# j7aen_main_ctrl_mmr0_CFG0 register map
Vendor: Texas Instruments
Registers are 32-bit, read-write, reset 0x0 unless marked. A register's access mark holds for its fields unless they carry their own. Offsets are as the file gives them; [hi:lo] are bit positions; {n}, {i} and the like mark numbered series; 'fields as' and 'values as' point back to an identical list.

## j7aen_main_ctrl_mmr0_CFG0 (part 2 of 2)
{0x8280+4i} CFG0_USART{i}_CLKSEL (i=0..6)
  [0] USART{i}_CLKSEL_CLK_SEL — Selects the clock source for UART{i}: Field values (others are reserved): 1'b0 - MAIN_PLL1_HSDIV0_CLKOUT Divider Output (See USART{i}_CLK_CTRL) 1'b1 - MAIN_PLL1_HSDIV1_CLKOUT
0x82B0 CFG0_ATL_CLKSEL
  [2:0] ATL_CLKSEL_PCLK_SEL — Selects the PCLK clock source Field values (others are reserved): 3'b000 - MAIN_PLL2_HSDIV8_CLKOUT 3'b001 - MAIN_PLL1_HSDIV6_CLKOUT 3'b010 - MAIN_PLL5_HSDIV1_CLKOUT 3'b100 - MAIN_PLL0_HSDIV7_CLKOUT 3'b101 - MCU_EXT_REFCLK0 (Pin) 3'b110 - EXT_REFCLK1 (Pin)
{0x82C0+4i} CFG0_ATL_BWS{i}_SEL (i=0..3)
  [3:0] ATL_BWS{i}_SEL_WD_SEL — BWS source signal Field values (others are reserved): 4'b0000 - MCASP0_AFSX_IN 4'b0001 - MCASP1_AFSX_IN 4'b0010 - MCASP2_AFSX_IN 4'b0011 - MCASP3_AFSX_IN 4'b0100 - MCASP4_AFSX_IN 4'b0101 - MCASP0_AFSX_IN 4'b0110 - MCASP1_AFSX_IN 4'b0111 - MCASP2_AFSX_IN 4'b1000 - MCASP3_AFSX_IN 4'b1001 - MCASP4_AFSX_IN 4'b1010 - AUDIO_EXT_REFCLK0_IN 4'b1011 - AUDIO_EXT_REFCLK1_IN 4'b1100 - AUDIO_EXT_REFCLK2_IN
{0x82D0+4i} CFG0_ATL_AWS{i}_SEL (i=0..3)
  [3:0] ATL_AWS{i}_SEL_WD_SEL — AWS source signal Field values (others are reserved): 4'b0000 - MCASP0_AFSX_IN 4'b0001 - MCASP1_AFSX_IN 4'b0010 - MCASP2_AFSX_IN 4'b0011 - MCASP3_AFSX_IN 4'b0100 - MCASP4_AFSX_IN 4'b0101 - MCASP0_AFSX_IN 4'b0110 - MCASP1_AFSX_IN 4'b0111 - MCASP2_AFSX_IN 4'b1000 - MCASP3_AFSX_IN 4'b1001 - MCASP4_AFSX_IN 4'b1010 - AUDIO_EXT_REFCLK0_IN 4'b1011 - AUDIO_EXT_REFCLK1_IN 4'b1100 - AUDIO_EXT_REFCLK2_IN
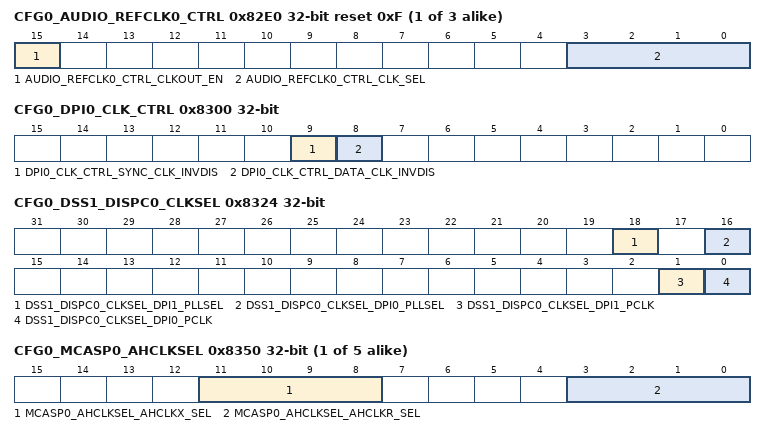
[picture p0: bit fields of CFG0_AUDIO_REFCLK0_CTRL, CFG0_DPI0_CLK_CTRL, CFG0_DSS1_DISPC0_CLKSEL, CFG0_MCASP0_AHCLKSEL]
{0x82E0+4i} CFG0_AUDIO_REFCLK{i}_CTRL reset 0xF (i=0..2)
  [15] AUDIO_REFCLK{i}_CTRL_CLKOUT_EN — AUDIO_REFCLK {i} output activate Field values (others are reserved): 1'b0 - INPUT 1'b1 - OUTPUT
  [3:0] AUDIO_REFCLK{i}_CTRL_CLK_SEL — Selects the source of AUDIO_REFCLK{i} Field values (others are reserved): 4'b0000 - MCASP0_AHCLKR 4'b0001 - MCASP1_AHCLKR 4'b0010 - MCASP2_AHCLKR 4'b0011 - MCASP3_AHCLKR 4'b0100 - MCASP4_AHCLKR 4'b0101 - MCASP0_AHCLKX 4'b0110 - MCASP1_AHCLKX 4'b0111 - MCASP2_AHCLKX 4'b1000 - MCASP3_AHCLKX 4'b1001 - MCASP4_AHCLKX 4'b1010 - ATCLK0 4'b1011 - ATCLK1 4'b1100 - ATCLK2 4'b1101 - ATCLK3 4'b1110 - MAIN_PLL1_HSDIV6_CLKOUT 4'b1111 - MAIN_PLL2_HSDIV8_CLKOUT
0x8300 CFG0_DPI0_CLK_CTRL
  [9] DPI0_CLK_CTRL_SYNC_CLK_INVDIS — Clock edge select for DPI0 HSYNC and VSYNC outputs. Value must match the programmed value of the DSS POL_FREQ.RF bitfield.8 Note that this value should be opposite of the programmed value of DSS POL_FREQ[16] RF. Field values (others are reserved): 1'b0 - FALLING 1'b1 - RISING
  [8] DPI0_CLK_CTRL_DATA_CLK_INVDIS — Clock edge select for DPI0 DATA and DE outputs Value must match the programmed value of the DSS POL_FREQ.IPC bitfield.0 Field values (others are reserved): 1'b0 - FALLING 1'b1 - RISING
0x8310 CFG0_DPHY0_CLKSEL
  [0] DPHY0_CLKSEL_REF_CLK_SEL — DPHY reference clock source Field values (others are reserved): 1'b0 - HFOSC0_CLKOUT_SERDES 1'b1 - MAIN_PLL0_HSDIV9_CLKOUT
0x8320 CFG0_DSS0_DISPC0_CLKSEL
  [1] DSS0_DISPC0_CLKSEL_DPI1_PCLK — DPI pixel Clock Source - DSS0_DISPC0_VP1 Field values (others are reserved): 1'b0 - MAIN_PLL17_HSDIV0_CLKOUT 1'b1 - VOUT0_EXTPCLKIN
0x8324 CFG0_DSS1_DISPC0_CLKSEL
  [18] DSS1_DISPC0_CLKSEL_DPI1_PLLSEL — When dpi1_pclk selection is PLL, Selects specific PLL Field values (others are reserved): 1'b0 - MAIN_PLL18_HSDIV0_CLKOUT 1'b1 - MAIN_PLL17_HSDIV0_CLKOUT
  [16] DSS1_DISPC0_CLKSEL_DPI0_PLLSEL — When dpi0_pclk selection is PLL, Selects specific PLL Field values (others are reserved): 1'b0 - MAIN_PLL18_HSDIV0_CLKOUT 1'b1 - MAIN_PLL17_HSDIV0_CLKOUT
  [1] DSS1_DISPC0_CLKSEL_DPI1_PCLK — DPI pixel Clock Source - DSS1_DISPC0_VP1 Field values (others are reserved): 1'b0 - PLL (Selected by dpi1_pllsel) 1'b1 - VOUT0_EXTPCLKIN
  [0] DSS1_DISPC0_CLKSEL_DPI0_PCLK — DPI pixel Clock Source - DSS1_DISPC0_VP0 Field values (others are reserved): 1'b0 - PLL (Selected by dpi0_pllsel) 1'b1 - VOUT0_EXTPCLKIN
0x8328 CFG0_OLDI1_CLKSEL
  [0] OLDI1_CLKSEL_CLKSEL — Selects the input (PLL) clock for OLDI1 Field values (others are reserved): 1'b0 - MAIN_PLL16_HSDIV0_CLKOUT 1'b1 - MAIN_PLL18_HSDIV0_CLKOUT
{0x8330+4i} CFG0_MCASP{i}_CLKSEL (i=0..4)
  [2:0] MCASP{i}_CLKSEL_AUXCLK_SEL — Selects the AUXCLK input source for McASP0 Field values (others are reserved): 3'b000 - MAIN_PLL2_HSDIV8_CLKOUT 3'b001 - MAIN_PLL1_HSDIV6_CLKOUT 3'b100 - ATCLK0 3'b101 - ATCLK1 3'b110 - ATCLK2 3'b111 - ATCLK3
{0x8350+4i} CFG0_MCASP{i}_AHCLKSEL (i=0..4)
  [11:8] MCASP{i}_AHCLKSEL_AHCLKX_SEL — Selects the AHCLKX input source for McASP{i} Field values (others are reserved): 4'b0000 - EXT_REFCLK1 (Pin) 4'b0001 - HFOSC0_CLKOUT 4'b0010 - AUDIO_EXT_REFCLK0 (Pin) 4'b0011 - AUDIO_EXT_REFCLK1 (Pin) 4'b0100 - AUDIO_EXT_REFCLK2 (Pin) 4'b0101 - ATCLK0 4'b0110 - ATCLK1 4'b0111 - ATCLK2 4'b1000 - ATCLK3
  [3:0] MCASP{i}_AHCLKSEL_AHCLKR_SEL — Selects the AHCLKR input source for McASP{i} Field values (others are reserved): 4'b0000 - EXT_REFCLK1 (Pin) 4'b0001 - HFOSC0_CLKOUT 4'b0010 - AUDIO_EXT_REFCLK0 (Pin) 4'b0011 - AUDIO_EXT_REFCLK1 (Pin) 4'b0100 - AUDIO_EXT_REFCLK2 (Pin) 4'b0101 - ATCLK0 4'b0110 - ATCLK1 4'b0111 - ATCLK2 4'b1000 - ATCLK3
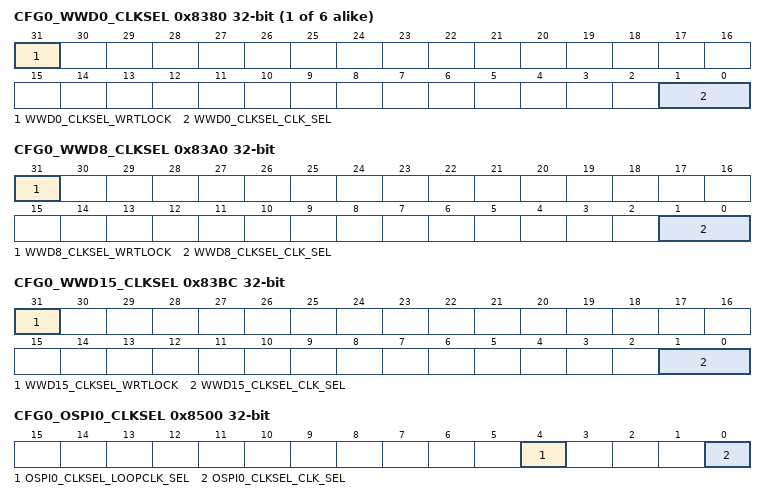
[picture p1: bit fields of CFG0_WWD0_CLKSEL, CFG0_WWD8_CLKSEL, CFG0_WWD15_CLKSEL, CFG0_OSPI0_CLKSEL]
{0x8380+4i} CFG0_WWD{i}_CLKSEL (i=0..5)
  [31] WWD{i}_CLKSEL_WRTLOCK — When set, locks WWD{i}_CLKSEL from further writes until the next module reset. Field values (others are reserved): 1'b0 - UNLOCKED 1'b1 - LOCKED
  [1:0] WWD{i}_CLKSEL_CLK_SEL — Windowed watchdog timer functional clock input select mux control Field values (others are reserved): 2'b00 - HFOSC0_CLKOUT 2'b01 - DEVICE_CLKOUT_32K 2'b10 - CLK_12M_RC 2'b11 - CLK_32K
0x83A0 CFG0_WWD8_CLKSEL
  [31] WWD8_CLKSEL_WRTLOCK — When set, locks WWD8_CLKSEL from further writes until the next module reset. Field values (others are reserved): 1'b0 - UNLOCKED 1'b1 - LOCKED
  [1:0] WWD8_CLKSEL_CLK_SEL — Windowed watchdog timer functional clock input select mux control Field values (others are reserved): 2'b00 - HFOSC0_CLKOUT 2'b01 - DEVICE_CLKOUT_32K 2'b10 - CLK_12M_RC 2'b11 - CLK_32K
0x83BC CFG0_WWD15_CLKSEL
  [31] WWD15_CLKSEL_WRTLOCK — When set, locks WWD15_CLKSEL from further writes until the next module reset. Field values (others are reserved): 1'b0 - UNLOCKED 1'b1 - LOCKED
  [1:0] WWD15_CLKSEL_CLK_SEL — Windowed watchdog timer functional clock input select mux control Field values (others are reserved): 2'b00 - HFOSC0_CLKOUT 2'b01 - DEVICE_CLKOUT_32K 2'b10 - CLK_12M_RC 2'b11 - CLK_32K
0x8400 CFG0_SERDES0_CLKSEL
  [1:0] SERDES0_CLKSEL_CORE_REFCLK_SEL — Selects the source for the core_refclk input Field values (others are reserved): 2'b00 - HFOSC0_CLKOUT_SERDES 2'b01 - EXT_REFCLK1 (Pin) 2'b10 - MAIN_PLL2_HSDIV0_CLKOUT 2'b11 - MAIN_PLL0_HSDIV9_CLKOUT
0x8410 CFG0_SERDES1_CLKSEL
  [1:0] SERDES1_CLKSEL_CORE_REFCLK_SEL — Selects the source for the core_refclk input Field values (others are reserved): 2'b00 - HFOSC0_CLKOUT_SERDES 2'b01 - EXT_REFCLK1 (Pin) 2'b10 - MAIN_PLL2_HSDIV0_CLKOUT 2'b11 - MAIN_PLL0_HSDIV9_CLKOUT
0x8480 CFG0_MCAN0_CLKSEL
  [1:0] MCAN0_CLKSEL_CLK_SEL — MAIN MCAN_CLK selection Field values (others are reserved): 2'b00 - MAIN_PLL0_HSDIV4_CLKOUT 2'b01 - MCU_EXT_REFCLK0 (Pin) 2'b10 - EXT_REFCLK1 (Pin) 2'b11 - HFOSC0_CLKOUT
0x8484 CFG0_MCAN1_CLKSEL
  [1:0] MCAN1_CLKSEL_CLK_SEL — MAIN MCAN_CLK selection Field values (others are reserved): 2'b00 - MAIN_PLL0_HSDIV4_CLKOUT 2'b01 - MCU_EXT_REFCLK0 (Pin) 2'b10 - EXT_REFCLK1 (Pin) 2'b11 - HFOSC0_CLKOUT
0x8500 CFG0_OSPI0_CLKSEL
  [4] OSPI0_CLKSEL_LOOPCLK_SEL — OBSPI0 Loopback clock source Field values (others are reserved): 1'b0 - Board Level Loopback 1'b1 - Internal Loopback
  [0] OSPI0_CLKSEL_CLK_SEL — OSPI0 reference clock selection Field values (others are reserved): 1'b0 - MAIN_PLL0_HSDIV1_CLKOUT 1'b1 - MAIN_PLL1_HSDIV5_CLKOUT
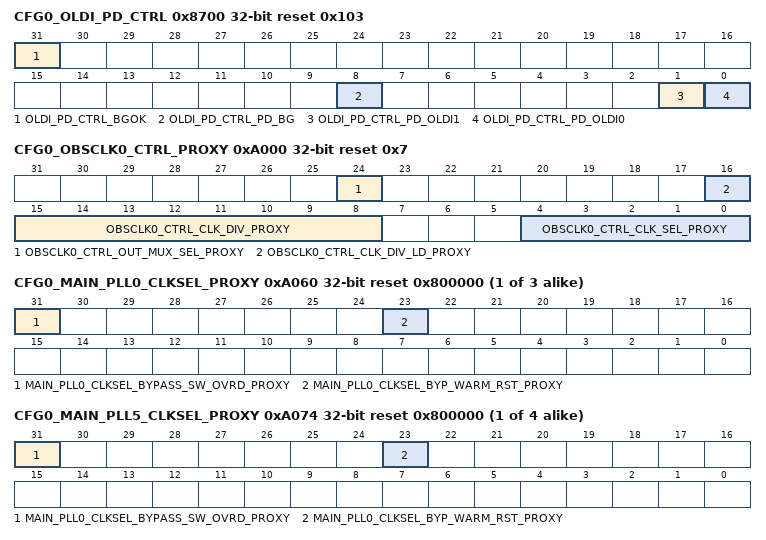
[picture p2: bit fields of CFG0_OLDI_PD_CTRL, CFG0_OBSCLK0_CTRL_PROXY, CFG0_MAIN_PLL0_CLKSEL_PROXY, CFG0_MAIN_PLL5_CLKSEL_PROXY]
0x8700 CFG0_OLDI_PD_CTRL access per field reset 0x103
  [31] OLDI_PD_CTRL_BGOK ro — OLDI Bandgap Reference Status Field values (others are reserved): 1'b0 - BG_NOT_READY 1'b1 - BG_READY
  [8] OLDI_PD_CTRL_PD_BG rw — Bandgap Power Down Field values (others are reserved): 1'b0 - BG_ON 1'b1 - BG_OFF
  [1] OLDI_PD_CTRL_PD_OLDI1 rw — Forces OLDI1 LVDS IOs to Power Down Field values (others are reserved): 1'b0 - LVDS_ON 1'b1 - LVDS_OFF
  [0] OLDI_PD_CTRL_PD_OLDI0 rw — Forces OLDI0 LVDS IOs to Power Down Field values (others are reserved): 1'b0 - LVDS_ON 1'b1 - LVDS_OFF
{0x9100+4i} CFG0_CLAIMREG_P2_R{i}_READONLY ro (i=0..14)
  [31:0] CLAIMREG_P2_R{i}_READONLY — Claim bits for Partition 2
0xA000 CFG0_OBSCLK0_CTRL_PROXY reset 0x7
  [24] OBSCLK0_CTRL_OUT_MUX_SEL_PROXY — OBSCLK pin output mux selection. HFOSC0_CLK is a direct output from the HFOSC0 Field values (others are reserved): 1'b0 - CLK_DIV_OUT 1'b1 - HFOSC0_CLK (clk_sel must be OFF)
  [16] OBSCLK0_CTRL_CLK_DIV_LD_PROXY — Load divisor value from clk_div field, when the bit is toggled from 0 to 1. Field values (others are reserved): 1'b0 - READY 1'b1 - LOAD
  [15:8] OBSCLK0_CTRL_CLK_DIV_PROXY — OBSCLK0 output divider. Sets divider to divide by clkdiv + 1. Divide by 1 to 256 are supported. After writing to this field, the clk_div_ld field must be toggled.
  [4:0] OBSCLK0_CTRL_CLK_SEL_PROXY — OBSCLK0 clock source selection. Selects the source of the clock to be divided by the OBSCLK0 divider. Field values (others are reserved): 5'b00000 - MAIN_PLL0_HSDIV0_CLKOUT 5'b00001 - MAIN_PLL1_HSDIV0_CLKOUT 5'b00010 - MAIN_PLL2_HSDIV0_CLKOUT 5'b00011 - MPUSS_CLK_DIV4 5'b00100 - DDRSS_CLK_DIV4 5'b00101 - CLK_12M_RC 5'b00110 - HFOSC0_CLKOUT_32K 5'b00111 - PLLCTRL_OBSCLK 5'b01000 - HFOSC0_CLKOUT 5'b01001 - CLK_32K_RC 5'b01010 - CPSW0_CPTS_GENF0 5'b01011 - CPSW0_CPTS_GENF1 5'b01100 - MCU_PLL0_HSDIV0_CLKOUT 5'b01101 - MAIN_PLL15_HSDIV0_CLKOUT 5'b01110 - MAIN_PLL16_HSDIV0_CLKOUT_DIV8 undefined - undefined 5'b01111 - MAIN_PLL17_HSDIV0_CLKOUT 5'b10000 - MAIN_SYSCLK0 5'b10001 - DEVICE_CLKOUT_32K 5'b10010 - MAIN_PLL5_HSDIV0_CLKOUT_DIV2 5'b10011 - C7XV256_CLK_DIV4 5'b10100 - MAIN_PLL6_HSDIV0_CLKOUT_DIV4 5'b10101 - MAIN_PLL18_HSDIV0_CLKOUT_DIV2 5'b11111 - OFF (Must Select this option when out_mux_sel is set to HFOSC0_CLK)
0xA010 CFG0_CLKOUT_CTRL_PROXY
  [0] CLKOUT_CTRL_CLK_SEL_PROXY — Selects CLKOUT clock source Field values (others are reserved): 1'b0 - MAIN_PLL2_HSDIV1_CLKOUT / 5 1'b1 - MAIN_PLL2_HSDIV1_CLKOUT / 10
{0xA060+4i} CFG0_MAIN_PLL{i}_CLKSEL_PROXY reset 0x800000 (i=0..2)
  [31] MAIN_PLL{i}_CLKSEL_BYPASS_SW_OVRD_PROXY — PLL Bypass warm reset software override When set, activates software control of exit from bypass mode on a main_reset_z for MAIN PLL{i}. This bit must not be set until after the corresponding byp_warm_rst bit has been cleared or the PLL will immediately enter bypass mode. Field values (others are reserved): 1'b0 - DEACTIVATE 1'b1 - ACTIVATE
  [23] MAIN_PLL{i}_CLKSEL_BYP_WARM_RST_PROXY — PLL bypass mode after warm reset. This bit is only valid when bypass_sw_ovrd is set to 1'b1 to activate bypass software override. This bit is set (1'b1) when a MAIN warm reset occurs and will keep MAIN PLL{i} in bypass mode after reset exit until cleared by software. Field values (others are reserved): 1'b0 - EXIT_BYPASS 1'b1 - MAINTAIN_BYPASS
{0xA060+4i} CFG0_MAIN_PLL{i}_CLKSEL_PROXY reset 0x800000 (i=5..8)
  fields as CFG0_MAIN_PLL0_CLKSEL_PROXY
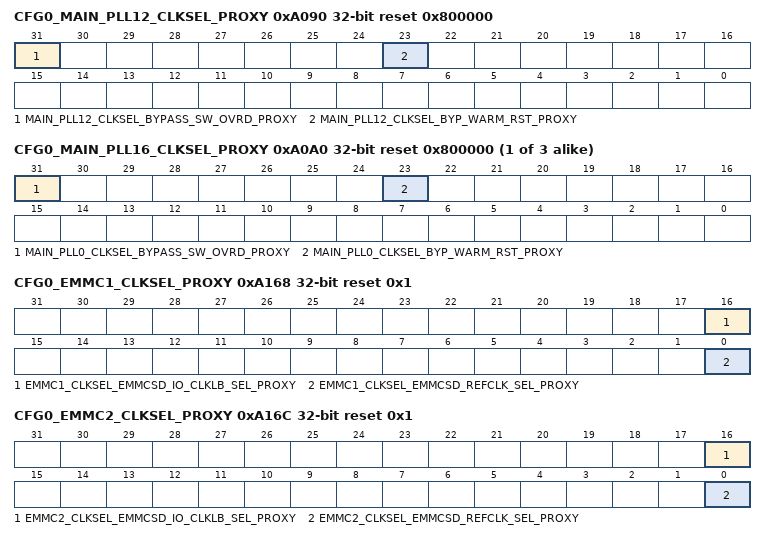
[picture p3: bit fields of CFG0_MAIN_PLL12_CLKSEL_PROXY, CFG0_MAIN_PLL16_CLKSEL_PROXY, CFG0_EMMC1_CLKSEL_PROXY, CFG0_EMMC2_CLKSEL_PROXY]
0xA090 CFG0_MAIN_PLL12_CLKSEL_PROXY reset 0x800000
  [31] MAIN_PLL12_CLKSEL_BYPASS_SW_OVRD_PROXY — PLL Bypass warm reset software override When set, activates software control of exit from bypass mode on a main_reset_z for MAIN PLL12. This bit must not be set until after the corresponding byp_warm_rst bit has been cleared or the PLL will immediately enter bypass mode. Field values (others are reserved): 1'b0 - DEACTIVATE 1'b1 - ACTIVATE
  [23] MAIN_PLL12_CLKSEL_BYP_WARM_RST_PROXY — PLL bypass mode after warm reset. This bit is only valid when bypass_sw_ovrd is set to 1'b1 to activate bypass software override. This bit is set (1'b1) when a MAIN warm reset occurs and will keep MAIN PLL12 in bypass mode after reset exit until cleared by software. Field values (others are reserved): 1'b0 - EXIT_BYPASS 1'b1 - MAINTAIN_BYPASS
{0xA060+4i} CFG0_MAIN_PLL{i}_CLKSEL_PROXY reset 0x800000 (i=16..18)
  fields as CFG0_MAIN_PLL0_CLKSEL_PROXY
0xA120 CFG0_PCIE0_CLKSEL_PROXY
  [2:0] PCIE0_CLKSEL_CPTS_CLKSEL_PROXY — Selects the clock source for the PCIE0 Common Platform Time Stamp module Field values (others are reserved): 3'b000 - MAIN_PLL2_HSDIV6_CLKOUT 3'b001 - MAIN_PLL0_HSDIV6_CLKOUT 3'b010 - CP_GEMAC_CPTS0_RFT_CLK (Pin) undefined - undefined 3'b011 - Reserved 3'b100 - MCU_EXT_REFCLK0 (Pin) 3'b101 - EXT_REFCLK1 (Pin) 3'b110 - SERDES1_IP1_LN0_TXMCLK 3'b111 - Reserved
0xA140 CFG0_CPSW_CLKSEL_PROXY reset 0x7
  [2:0] CPSW_CLKSEL_CPTS_CLKSEL_PROXY — Selects the clock source for the CPSW Ethernet switch Common Platform Time Stamp module Field values (others are reserved): 3'b000 - MAIN_PLL2_HSDIV5_CLKOUT 3'b001 - MAIN_PLL0_HSDIV6_CLKOUT 3'b010 - CP_GEMAC_CPTS0_RFT_CLK (Pin) 3'b011 - Reserved 3'b100 - MCU_EXT_REFCLK0 (Pin) 3'b101 - EXT_REFCLK1 (Pin) 3'b110 - SERDES0_IP1_LN0_TXMCLK undefined - undefined 3'b111 - MAIN_SYSCLK0
0xA160 CFG0_EMMC0_CLKSEL_PROXY
  [0] EMMC0_CLKSEL_EMMCSD_REFCLK_SEL_PROXY — Selects the functional clock for the MMC Module Field values (others are reserved): 1'b0 - MAIN_PLL0_HSDIV5_CLKOUT 1'b1 - MAIN_PLL2_HSDIV2_CLKOUT
0xA168 CFG0_EMMC1_CLKSEL_PROXY reset 0x1
  [16] EMMC1_CLKSEL_EMMCSD_IO_CLKLB_SEL_PROXY — Selects IO Pad Loopback for the MMC Module Field values (others are reserved): 1'b0 - Loopback from Unbonded Pad MMCSD1_CLKLB 1'b1 - Loopback from IO Pin MMCSD1_CLK
  [0] EMMC1_CLKSEL_EMMCSD_REFCLK_SEL_PROXY — Selects the functional clock for the MMC Module Field values (others are reserved): 1'b0 - MAIN_PLL0_HSDIV5_CLKOUT 1'b1 - MAIN_PLL2_HSDIV2_CLKOUT
0xA16C CFG0_EMMC2_CLKSEL_PROXY reset 0x1
  [16] EMMC2_CLKSEL_EMMCSD_IO_CLKLB_SEL_PROXY — Selects IO Pad Loopback for the MMC Module Field values (others are reserved): 1'b0 - Loopback from Unbonded Pad MMCSD2_CLKLB 1'b1 - Loopback from IO Pin MMCSD2_CLK
  [0] EMMC2_CLKSEL_EMMCSD_REFCLK_SEL_PROXY — Selects the functional clock for the MMC Module Field values (others are reserved): 1'b0 - MAIN_PLL0_HSDIV5_CLKOUT 1'b1 - MAIN_PLL2_HSDIV2_CLKOUT
0xA180 CFG0_GPMC_CLKSEL_PROXY
  [0] GPMC_CLKSEL_CLK_SEL_PROXY — Selects the GPMC clock source: Field values (others are reserved): 1'b0 - MAIN_PLL0_HSDIV3_CLKOUT 1'b1 - MAIN_PLL2_HSDIV7_CLKOUT
{0xA1B0+4i} CFG0_TIMER{i}_CLKSEL_PROXY (i=0..7)
  [3:0] TIMER{i}_CLKSEL_CLK_SEL_PROXY — Timer functional clock input select mux control (Reserved values default to HFOSC0_CLK) Field values (others are reserved): 4'b0000 - HFOSC0_CLKOUT 4'b0001 - DEVICE_CLKOUT_32K 4'b0010 - MAIN_PLL0_HSDIV7_CLKOUT 4'b0011 - CLK_12M_RC 4'b0100 - MCU_EXT_REFCLK0 (Pin) 4'b0101 - EXT_REFCLK1 (Pin) 4'b0110 - Reserved 4'b0111 - CP_GEMAC_CPTS0_RFT_CLK (Pin) 4'b1000 - MAIN_PLL1_HSDIV3_CLKOUT 4'b1001 - MAIN_PLL2_HSDIV6_CLKOUT 4'b1010 - CPSW0_CPTS_GENF0 4'b1011 - CPSW0_CPTS_GENF1 4'b1100 - MAIN_PLL5_HSDIV1_CLKOUT
{0xA200+4i} CFG0_SPI{i}_CLKSEL_PROXY (i=0..2)
  [16] SPI{i}_CLKSEL_MSTR_LB_CLKSEL_PROXY — Controller mode receive capture clock loopback selection Field values (others are reserved): 1'b0 - INTERNAL_LOOPBACK 1'b1 - EXTERNAL_LOOPBACK
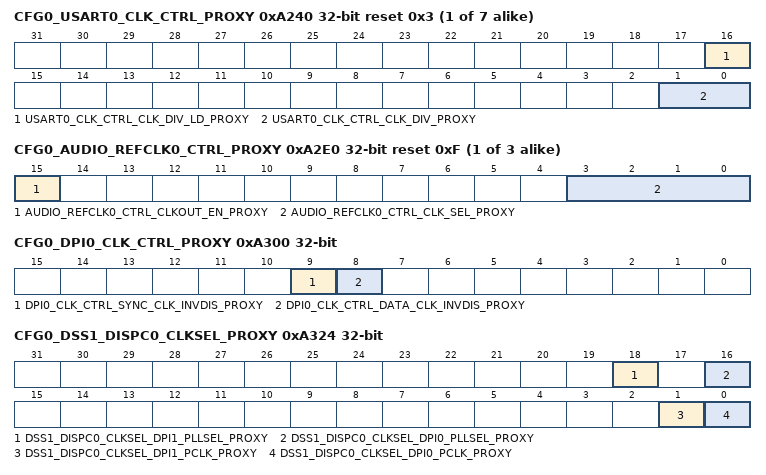
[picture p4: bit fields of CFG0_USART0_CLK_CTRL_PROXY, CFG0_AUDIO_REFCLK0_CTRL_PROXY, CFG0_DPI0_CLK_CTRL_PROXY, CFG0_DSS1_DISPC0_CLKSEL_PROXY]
{0xA240+4i} CFG0_USART{i}_CLK_CTRL_PROXY reset 0x3 (i=0..6)
  [16] USART{i}_CLK_CTRL_CLK_DIV_LD_PROXY — Load the output divider value Writing 1 to this bit will generate a load pulse to load the USART{i} clock programmable divider value. This bit can be cleared but must not be set in the same write cycle in which the clk_div value is changed. Field values (others are reserved): 1'b0 - READY 1'b1 - LOAD
  [1:0] USART{i}_CLK_CTRL_CLK_DIV_PROXY — Selects the clock divider value. Supports divide values of 1 to 4 Default is /4. To load the new divider value the clk_div_ld bit must be cleared and then set to 1. Field values (others are reserved): 2'b00 - Divide by 1 2'b01 - Divide by 2 2'b10 - Divide by 3 2'b11 - Divide by 4
{0xA280+4i} CFG0_USART{i}_CLKSEL_PROXY (i=0..6)
  [0] USART{i}_CLKSEL_CLK_SEL_PROXY — Selects the clock source for UART{i}: Field values (others are reserved): 1'b0 - MAIN_PLL1_HSDIV0_CLKOUT Divider Output (See USART{i}_CLK_CTRL) 1'b1 - MAIN_PLL1_HSDIV1_CLKOUT
0xA2B0 CFG0_ATL_CLKSEL_PROXY
  [2:0] ATL_CLKSEL_PCLK_SEL_PROXY — Selects the PCLK clock source Field values (others are reserved): 3'b000 - MAIN_PLL2_HSDIV8_CLKOUT 3'b001 - MAIN_PLL1_HSDIV6_CLKOUT 3'b010 - MAIN_PLL5_HSDIV1_CLKOUT 3'b100 - MAIN_PLL0_HSDIV7_CLKOUT 3'b101 - MCU_EXT_REFCLK0 (Pin) 3'b110 - EXT_REFCLK1 (Pin)
{0xA2C0+4i} CFG0_ATL_BWS{i}_SEL_PROXY (i=0..3)
  [3:0] ATL_BWS{i}_SEL_WD_SEL_PROXY — BWS source signal Field values (others are reserved): 4'b0000 - MCASP0_AFSX_IN 4'b0001 - MCASP1_AFSX_IN 4'b0010 - MCASP2_AFSX_IN 4'b0011 - MCASP3_AFSX_IN 4'b0100 - MCASP4_AFSX_IN 4'b0101 - MCASP0_AFSX_IN 4'b0110 - MCASP1_AFSX_IN 4'b0111 - MCASP2_AFSX_IN 4'b1000 - MCASP3_AFSX_IN 4'b1001 - MCASP4_AFSX_IN 4'b1010 - AUDIO_EXT_REFCLK0_IN 4'b1011 - AUDIO_EXT_REFCLK1_IN 4'b1100 - AUDIO_EXT_REFCLK2_IN
{0xA2D0+4i} CFG0_ATL_AWS{i}_SEL_PROXY (i=0..3)
  [3:0] ATL_AWS{i}_SEL_WD_SEL_PROXY — AWS source signal Field values (others are reserved): 4'b0000 - MCASP0_AFSX_IN 4'b0001 - MCASP1_AFSX_IN 4'b0010 - MCASP2_AFSX_IN 4'b0011 - MCASP3_AFSX_IN 4'b0100 - MCASP4_AFSX_IN 4'b0101 - MCASP0_AFSX_IN 4'b0110 - MCASP1_AFSX_IN 4'b0111 - MCASP2_AFSX_IN 4'b1000 - MCASP3_AFSX_IN 4'b1001 - MCASP4_AFSX_IN 4'b1010 - AUDIO_EXT_REFCLK0_IN 4'b1011 - AUDIO_EXT_REFCLK1_IN 4'b1100 - AUDIO_EXT_REFCLK2_IN
{0xA2E0+4i} CFG0_AUDIO_REFCLK{i}_CTRL_PROXY reset 0xF (i=0..2)
  [15] AUDIO_REFCLK{i}_CTRL_CLKOUT_EN_PROXY — AUDIO_REFCLK {i} output activate Field values (others are reserved): 1'b0 - INPUT 1'b1 - OUTPUT
  [3:0] AUDIO_REFCLK{i}_CTRL_CLK_SEL_PROXY — Selects the source of AUDIO_REFCLK{i} Field values (others are reserved): 4'b0000 - MCASP0_AHCLKR 4'b0001 - MCASP1_AHCLKR 4'b0010 - MCASP2_AHCLKR 4'b0011 - MCASP3_AHCLKR 4'b0100 - MCASP4_AHCLKR 4'b0101 - MCASP0_AHCLKX 4'b0110 - MCASP1_AHCLKX 4'b0111 - MCASP2_AHCLKX 4'b1000 - MCASP3_AHCLKX 4'b1001 - MCASP4_AHCLKX 4'b1010 - ATCLK0 4'b1011 - ATCLK1 4'b1100 - ATCLK2 4'b1101 - ATCLK3 4'b1110 - MAIN_PLL1_HSDIV6_CLKOUT 4'b1111 - MAIN_PLL2_HSDIV8_CLKOUT
0xA300 CFG0_DPI0_CLK_CTRL_PROXY
  [9] DPI0_CLK_CTRL_SYNC_CLK_INVDIS_PROXY — Clock edge select for DPI0 HSYNC and VSYNC outputs. Value must match the programmed value of the DSS POL_FREQ.RF bitfield.8 Note that this value should be opposite of the programmed value of DSS POL_FREQ[16] RF. Field values (others are reserved): 1'b0 - FALLING 1'b1 - RISING
  [8] DPI0_CLK_CTRL_DATA_CLK_INVDIS_PROXY — Clock edge select for DPI0 DATA and DE outputs Value must match the programmed value of the DSS POL_FREQ.IPC bitfield.0 Field values (others are reserved): 1'b0 - FALLING 1'b1 - RISING
0xA310 CFG0_DPHY0_CLKSEL_PROXY
  [0] DPHY0_CLKSEL_REF_CLK_SEL_PROXY — DPHY reference clock source Field values (others are reserved): 1'b0 - HFOSC0_CLKOUT_SERDES 1'b1 - MAIN_PLL0_HSDIV9_CLKOUT
0xA320 CFG0_DSS0_DISPC0_CLKSEL_PROXY
  [1] DSS0_DISPC0_CLKSEL_DPI1_PCLK_PROXY — DPI pixel Clock Source - DSS0_DISPC0_VP1 Field values (others are reserved): 1'b0 - MAIN_PLL17_HSDIV0_CLKOUT 1'b1 - VOUT0_EXTPCLKIN
0xA324 CFG0_DSS1_DISPC0_CLKSEL_PROXY
  [18] DSS1_DISPC0_CLKSEL_DPI1_PLLSEL_PROXY — When dpi1_pclk selection is PLL, Selects specific PLL Field values (others are reserved): 1'b0 - MAIN_PLL18_HSDIV0_CLKOUT 1'b1 - MAIN_PLL17_HSDIV0_CLKOUT
  [16] DSS1_DISPC0_CLKSEL_DPI0_PLLSEL_PROXY — When dpi0_pclk selection is PLL, Selects specific PLL Field values (others are reserved): 1'b0 - MAIN_PLL18_HSDIV0_CLKOUT 1'b1 - MAIN_PLL17_HSDIV0_CLKOUT
  [1] DSS1_DISPC0_CLKSEL_DPI1_PCLK_PROXY — DPI pixel Clock Source - DSS1_DISPC0_VP1 Field values (others are reserved): 1'b0 - PLL (Selected by dpi1_pllsel) 1'b1 - VOUT0_EXTPCLKIN
  [0] DSS1_DISPC0_CLKSEL_DPI0_PCLK_PROXY — DPI pixel Clock Source - DSS1_DISPC0_VP0 Field values (others are reserved): 1'b0 - PLL (Selected by dpi0_pllsel) 1'b1 - VOUT0_EXTPCLKIN
0xA328 CFG0_OLDI1_CLKSEL_PROXY
  [0] OLDI1_CLKSEL_CLKSEL_PROXY — Selects the input (PLL) clock for OLDI1 Field values (others are reserved): 1'b0 - MAIN_PLL16_HSDIV0_CLKOUT 1'b1 - MAIN_PLL18_HSDIV0_CLKOUT
{0xA330+4i} CFG0_MCASP{i}_CLKSEL_PROXY (i=0..4)
  [2:0] MCASP{i}_CLKSEL_AUXCLK_SEL_PROXY — Selects the AUXCLK input source for McASP0 Field values (others are reserved): 3'b000 - MAIN_PLL2_HSDIV8_CLKOUT 3'b001 - MAIN_PLL1_HSDIV6_CLKOUT 3'b100 - ATCLK0 3'b101 - ATCLK1 3'b110 - ATCLK2 3'b111 - ATCLK3
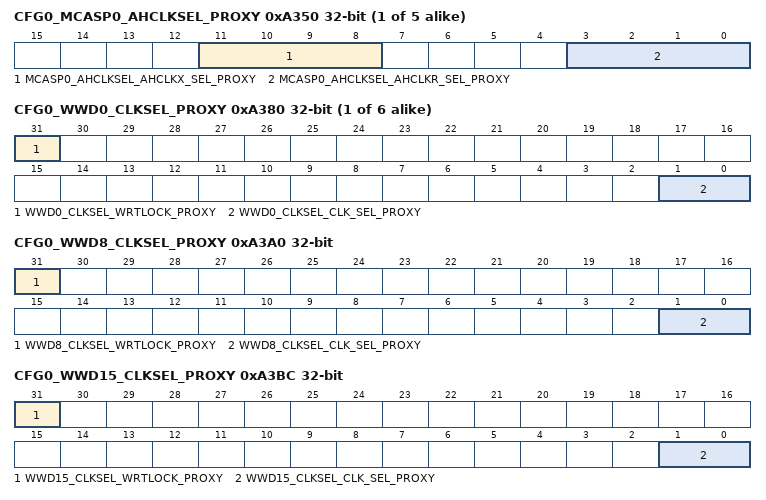
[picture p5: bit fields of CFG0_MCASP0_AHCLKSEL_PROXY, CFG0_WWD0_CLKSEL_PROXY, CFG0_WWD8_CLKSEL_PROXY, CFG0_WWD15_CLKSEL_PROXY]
{0xA350+4i} CFG0_MCASP{i}_AHCLKSEL_PROXY (i=0..4)
  [11:8] MCASP{i}_AHCLKSEL_AHCLKX_SEL_PROXY — Selects the AHCLKX input source for McASP{i} Field values (others are reserved): 4'b0000 - EXT_REFCLK1 (Pin) 4'b0001 - HFOSC0_CLKOUT 4'b0010 - AUDIO_EXT_REFCLK0 (Pin) 4'b0011 - AUDIO_EXT_REFCLK1 (Pin) 4'b0100 - AUDIO_EXT_REFCLK2 (Pin) 4'b0101 - ATCLK0 4'b0110 - ATCLK1 4'b0111 - ATCLK2 4'b1000 - ATCLK3
  [3:0] MCASP{i}_AHCLKSEL_AHCLKR_SEL_PROXY — Selects the AHCLKR input source for McASP{i} Field values (others are reserved): 4'b0000 - EXT_REFCLK1 (Pin) 4'b0001 - HFOSC0_CLKOUT 4'b0010 - AUDIO_EXT_REFCLK0 (Pin) 4'b0011 - AUDIO_EXT_REFCLK1 (Pin) 4'b0100 - AUDIO_EXT_REFCLK2 (Pin) 4'b0101 - ATCLK0 4'b0110 - ATCLK1 4'b0111 - ATCLK2 4'b1000 - ATCLK3
{0xA380+4i} CFG0_WWD{i}_CLKSEL_PROXY (i=0..5)
  [31] WWD{i}_CLKSEL_WRTLOCK_PROXY — When set, locks WWD{i}_CLKSEL from further writes until the next module reset. Field values (others are reserved): 1'b0 - UNLOCKED 1'b1 - LOCKED
  [1:0] WWD{i}_CLKSEL_CLK_SEL_PROXY — Windowed watchdog timer functional clock input select mux control Field values (others are reserved): 2'b00 - HFOSC0_CLKOUT 2'b01 - DEVICE_CLKOUT_32K 2'b10 - CLK_12M_RC 2'b11 - CLK_32K
0xA3A0 CFG0_WWD8_CLKSEL_PROXY
  [31] WWD8_CLKSEL_WRTLOCK_PROXY — When set, locks WWD8_CLKSEL from further writes until the next module reset. Field values (others are reserved): 1'b0 - UNLOCKED 1'b1 - LOCKED
  [1:0] WWD8_CLKSEL_CLK_SEL_PROXY — Windowed watchdog timer functional clock input select mux control Field values (others are reserved): 2'b00 - HFOSC0_CLKOUT 2'b01 - DEVICE_CLKOUT_32K 2'b10 - CLK_12M_RC 2'b11 - CLK_32K
0xA3BC CFG0_WWD15_CLKSEL_PROXY
  [31] WWD15_CLKSEL_WRTLOCK_PROXY — When set, locks WWD15_CLKSEL from further writes until the next module reset. Field values (others are reserved): 1'b0 - UNLOCKED 1'b1 - LOCKED
  [1:0] WWD15_CLKSEL_CLK_SEL_PROXY — Windowed watchdog timer functional clock input select mux control Field values (others are reserved): 2'b00 - HFOSC0_CLKOUT 2'b01 - DEVICE_CLKOUT_32K 2'b10 - CLK_12M_RC 2'b11 - CLK_32K
0xA400 CFG0_SERDES0_CLKSEL_PROXY
  [1:0] SERDES0_CLKSEL_CORE_REFCLK_SEL_PROXY — Selects the source for the core_refclk input Field values (others are reserved): 2'b00 - HFOSC0_CLKOUT_SERDES 2'b01 - EXT_REFCLK1 (Pin) 2'b10 - MAIN_PLL2_HSDIV0_CLKOUT 2'b11 - MAIN_PLL0_HSDIV9_CLKOUT
0xA410 CFG0_SERDES1_CLKSEL_PROXY
  [1:0] SERDES1_CLKSEL_CORE_REFCLK_SEL_PROXY — Selects the source for the core_refclk input Field values (others are reserved): 2'b00 - HFOSC0_CLKOUT_SERDES 2'b01 - EXT_REFCLK1 (Pin) 2'b10 - MAIN_PLL2_HSDIV0_CLKOUT 2'b11 - MAIN_PLL0_HSDIV9_CLKOUT
0xA480 CFG0_MCAN0_CLKSEL_PROXY
  [1:0] MCAN0_CLKSEL_CLK_SEL_PROXY — MAIN MCAN_CLK selection Field values (others are reserved): 2'b00 - MAIN_PLL0_HSDIV4_CLKOUT 2'b01 - MCU_EXT_REFCLK0 (Pin) 2'b10 - EXT_REFCLK1 (Pin) 2'b11 - HFOSC0_CLKOUT
0xA484 CFG0_MCAN1_CLKSEL_PROXY
  [1:0] MCAN1_CLKSEL_CLK_SEL_PROXY — MAIN MCAN_CLK selection Field values (others are reserved): 2'b00 - MAIN_PLL0_HSDIV4_CLKOUT 2'b01 - MCU_EXT_REFCLK0 (Pin) 2'b10 - EXT_REFCLK1 (Pin) 2'b11 - HFOSC0_CLKOUT
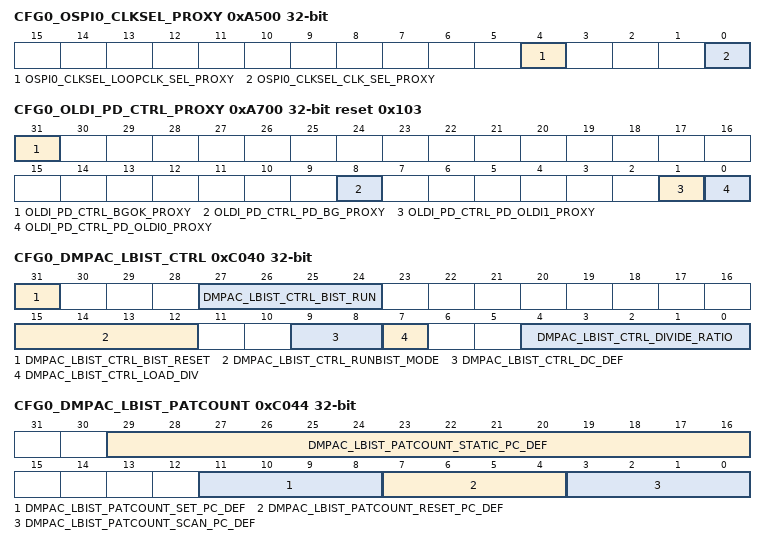
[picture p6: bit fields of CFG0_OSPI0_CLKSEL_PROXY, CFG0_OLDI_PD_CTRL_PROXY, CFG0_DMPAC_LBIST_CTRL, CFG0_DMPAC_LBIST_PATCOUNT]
0xA500 CFG0_OSPI0_CLKSEL_PROXY
  [4] OSPI0_CLKSEL_LOOPCLK_SEL_PROXY — OBSPI0 Loopback clock source Field values (others are reserved): 1'b0 - Board Level Loopback 1'b1 - Internal Loopback
  [0] OSPI0_CLKSEL_CLK_SEL_PROXY — OSPI0 reference clock selection Field values (others are reserved): 1'b0 - MAIN_PLL0_HSDIV1_CLKOUT 1'b1 - MAIN_PLL1_HSDIV5_CLKOUT
0xA700 CFG0_OLDI_PD_CTRL_PROXY access per field reset 0x103
  [31] OLDI_PD_CTRL_BGOK_PROXY ro — OLDI Bandgap Reference Status Field values (others are reserved): 1'b0 - BG_NOT_READY 1'b1 - BG_READY
  [8] OLDI_PD_CTRL_PD_BG_PROXY rw — Bandgap Power Down Field values (others are reserved): 1'b0 - BG_ON 1'b1 - BG_OFF
  [1] OLDI_PD_CTRL_PD_OLDI1_PROXY rw — Forces OLDI1 LVDS IOs to Power Down Field values (others are reserved): 1'b0 - LVDS_ON 1'b1 - LVDS_OFF
  [0] OLDI_PD_CTRL_PD_OLDI0_PROXY rw — Forces OLDI0 LVDS IOs to Power Down Field values (others are reserved): 1'b0 - LVDS_ON 1'b1 - LVDS_OFF
{0xB100+4i} CFG0_CLAIMREG_P2_R{i} (i=0..14)
  [31:0] CLAIMREG_P2_R{i} — Claim bits for Partition 2
0xC040 CFG0_DMPAC_LBIST_CTRL
  [31] DMPAC_LBIST_CTRL_BIST_RESET — Reset LBIST macro
  [27:24] DMPAC_LBIST_CTRL_BIST_RUN — Starts LBIST if all bits are 1
  [15:12] DMPAC_LBIST_CTRL_RUNBIST_MODE — Runbist mode enable if all bits are 1
  [9:8] DMPAC_LBIST_CTRL_DC_DEF — Clock delay after scan_enable switching
  [7] DMPAC_LBIST_CTRL_LOAD_DIV — Loads LBIST clock divide ratio on transition from 0 to 1
  [4:0] DMPAC_LBIST_CTRL_DIVIDE_RATIO — LBIST clock divide ratio
0xC044 CFG0_DMPAC_LBIST_PATCOUNT
  [29:16] DMPAC_LBIST_PATCOUNT_STATIC_PC_DEF — Number of stuck-at patterns to run
  [11:8] DMPAC_LBIST_PATCOUNT_SET_PC_DEF — Number of set patterns to run
  [7:4] DMPAC_LBIST_PATCOUNT_RESET_PC_DEF — Number of reset patterns to run
  [3:0] DMPAC_LBIST_PATCOUNT_SCAN_PC_DEF — Number of chain test patterns to run
0xC048 CFG0_DMPAC_LBIST_SEED0
  [31:0] DMPAC_LBIST_SEED0_PRPG_DEF — Initial seed for PRPG (bits 31:0)
0xC04C CFG0_DMPAC_LBIST_SEED1
  [20:0] DMPAC_LBIST_SEED1_PRPG_DEF — Initial seed for PRPG (bits 52:32)
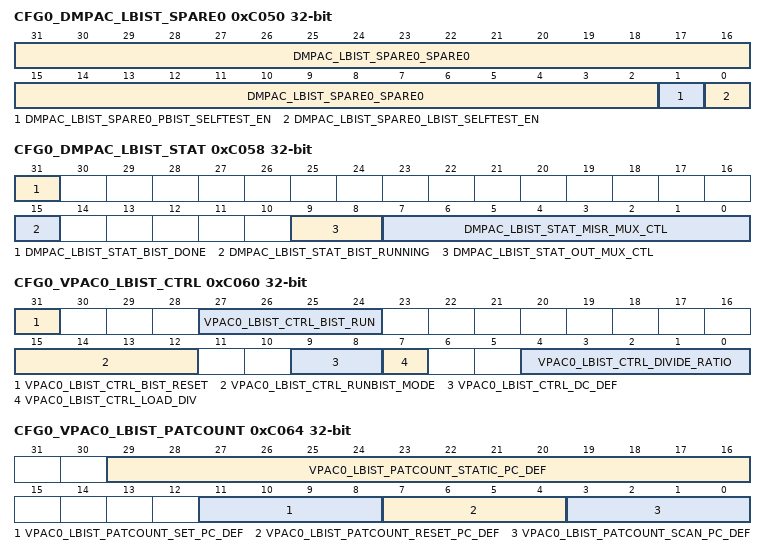
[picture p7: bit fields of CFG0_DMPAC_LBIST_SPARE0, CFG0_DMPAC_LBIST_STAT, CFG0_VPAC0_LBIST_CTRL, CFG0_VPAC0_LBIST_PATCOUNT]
0xC050 CFG0_DMPAC_LBIST_SPARE0
  [31:2] DMPAC_LBIST_SPARE0_SPARE0 — LBIST spare bits
  [1] DMPAC_LBIST_SPARE0_PBIST_SELFTEST_EN — PBIST isolation control
  [0] DMPAC_LBIST_SPARE0_LBIST_SELFTEST_EN — LBIST isolation control
0xC054 CFG0_DMPAC_LBIST_SPARE1
  [31:0] DMPAC_LBIST_SPARE1_SPARE1 — LBIST spare bits
0xC058 CFG0_DMPAC_LBIST_STAT access per field
  [31] DMPAC_LBIST_STAT_BIST_DONE ro — LBIST is done
  [15] DMPAC_LBIST_STAT_BIST_RUNNING ro — LBIST is running
  [9:8] DMPAC_LBIST_STAT_OUT_MUX_CTL rw — Selects source of LBIST output 00 - LBIST IP PID value 01 - LBIST CTRL ID value 1x - MISR value
  [7:0] DMPAC_LBIST_STAT_MISR_MUX_CTL rw — Selects block of 32 MISR bits to read. A value of 0 selects a compacted 32-bit version of the full MISR. A value of 1-32 select a 32-bit segment of the MISR.
0xC05C CFG0_DMPAC_LBIST_MISR ro
  [31:0] DMPAC_LBIST_MISR_MISR_RESULT — 32-bits of MISR value selected by misr_mux_ctl
0xC060 CFG0_VPAC0_LBIST_CTRL
  [31] VPAC0_LBIST_CTRL_BIST_RESET — Reset LBIST macro
  [27:24] VPAC0_LBIST_CTRL_BIST_RUN — Starts LBIST if all bits are 1
  [15:12] VPAC0_LBIST_CTRL_RUNBIST_MODE — Runbist mode enable if all bits are 1
  [9:8] VPAC0_LBIST_CTRL_DC_DEF — Clock delay after scan_enable switching
  [7] VPAC0_LBIST_CTRL_LOAD_DIV — Loads LBIST clock divide ratio on transition from 0 to 1
  [4:0] VPAC0_LBIST_CTRL_DIVIDE_RATIO — LBIST clock divide ratio
0xC064 CFG0_VPAC0_LBIST_PATCOUNT
  [29:16] VPAC0_LBIST_PATCOUNT_STATIC_PC_DEF — Number of stuck-at patterns to run
  [11:8] VPAC0_LBIST_PATCOUNT_SET_PC_DEF — Number of set patterns to run
  [7:4] VPAC0_LBIST_PATCOUNT_RESET_PC_DEF — Number of reset patterns to run
  [3:0] VPAC0_LBIST_PATCOUNT_SCAN_PC_DEF — Number of chain test patterns to run
0xC068 CFG0_VPAC0_LBIST_SEED0
  [31:0] VPAC0_LBIST_SEED0_PRPG_DEF — Initial seed for PRPG (bits 31:0)
0xC06C CFG0_VPAC0_LBIST_SEED1
  [20:0] VPAC0_LBIST_SEED1_PRPG_DEF — Initial seed for PRPG (bits 52:32)
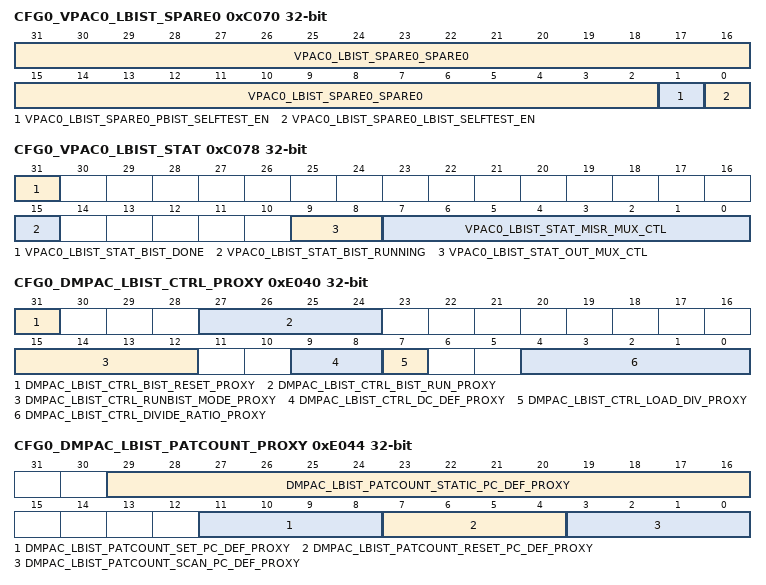
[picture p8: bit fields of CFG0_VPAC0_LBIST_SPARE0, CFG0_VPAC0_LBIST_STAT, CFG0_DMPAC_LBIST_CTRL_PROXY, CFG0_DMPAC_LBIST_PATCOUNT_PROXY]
0xC070 CFG0_VPAC0_LBIST_SPARE0
  [31:2] VPAC0_LBIST_SPARE0_SPARE0 — LBIST spare bits
  [1] VPAC0_LBIST_SPARE0_PBIST_SELFTEST_EN — PBIST isolation control
  [0] VPAC0_LBIST_SPARE0_LBIST_SELFTEST_EN — LBIST isolation control
0xC074 CFG0_VPAC0_LBIST_SPARE1
  [31:0] VPAC0_LBIST_SPARE1_SPARE1 — LBIST spare bits
0xC078 CFG0_VPAC0_LBIST_STAT access per field
  [31] VPAC0_LBIST_STAT_BIST_DONE ro — LBIST is done
  [15] VPAC0_LBIST_STAT_BIST_RUNNING ro — LBIST is running
  [9:8] VPAC0_LBIST_STAT_OUT_MUX_CTL rw — Selects source of LBIST output 00 - LBIST IP PID value 01 - LBIST CTRL ID value 1x - MISR value
  [7:0] VPAC0_LBIST_STAT_MISR_MUX_CTL rw — Selects block of 32 MISR bits to read. A value of 0 selects a compacted 32-bit version of the full MISR. A value of 1-32 select a 32-bit segment of the MISR.
0xC07C CFG0_VPAC0_LBIST_MISR ro
  [31:0] VPAC0_LBIST_MISR_MISR_RESULT — 32-bits of MISR value selected by misr_mux_ctl
0xC288 CFG0_DMPAC_LBIST_SIG ro
  [31:0] DMPAC_LBIST_SIG_MISR_SIG — MISR signature
0xC28C CFG0_VPAC0_LBIST_SIG ro
  [31:0] VPAC0_LBIST_SIG_MISR_SIG — MISR signature
{0xD100+4i} CFG0_CLAIMREG_P3_R{i}_READONLY ro (i=0..5)
  [31:0] CLAIMREG_P3_R{i}_READONLY — Claim bits for Partition 3
0xE040 CFG0_DMPAC_LBIST_CTRL_PROXY
  [31] DMPAC_LBIST_CTRL_BIST_RESET_PROXY — Reset LBIST macro
  [27:24] DMPAC_LBIST_CTRL_BIST_RUN_PROXY — Starts LBIST if all bits are 1
  [15:12] DMPAC_LBIST_CTRL_RUNBIST_MODE_PROXY — Runbist mode enable if all bits are 1
  [9:8] DMPAC_LBIST_CTRL_DC_DEF_PROXY — Clock delay after scan_enable switching
  [7] DMPAC_LBIST_CTRL_LOAD_DIV_PROXY — Loads LBIST clock divide ratio on transition from 0 to 1
  [4:0] DMPAC_LBIST_CTRL_DIVIDE_RATIO_PROXY — LBIST clock divide ratio
0xE044 CFG0_DMPAC_LBIST_PATCOUNT_PROXY
  [29:16] DMPAC_LBIST_PATCOUNT_STATIC_PC_DEF_PROXY — Number of stuck-at patterns to run
  [11:8] DMPAC_LBIST_PATCOUNT_SET_PC_DEF_PROXY — Number of set patterns to run
  [7:4] DMPAC_LBIST_PATCOUNT_RESET_PC_DEF_PROXY — Number of reset patterns to run
  [3:0] DMPAC_LBIST_PATCOUNT_SCAN_PC_DEF_PROXY — Number of chain test patterns to run
0xE048 CFG0_DMPAC_LBIST_SEED0_PROXY
  [31:0] DMPAC_LBIST_SEED0_PRPG_DEF_PROXY — Initial seed for PRPG (bits 31:0)
0xE04C CFG0_DMPAC_LBIST_SEED1_PROXY
  [20:0] DMPAC_LBIST_SEED1_PRPG_DEF_PROXY — Initial seed for PRPG (bits 52:32)
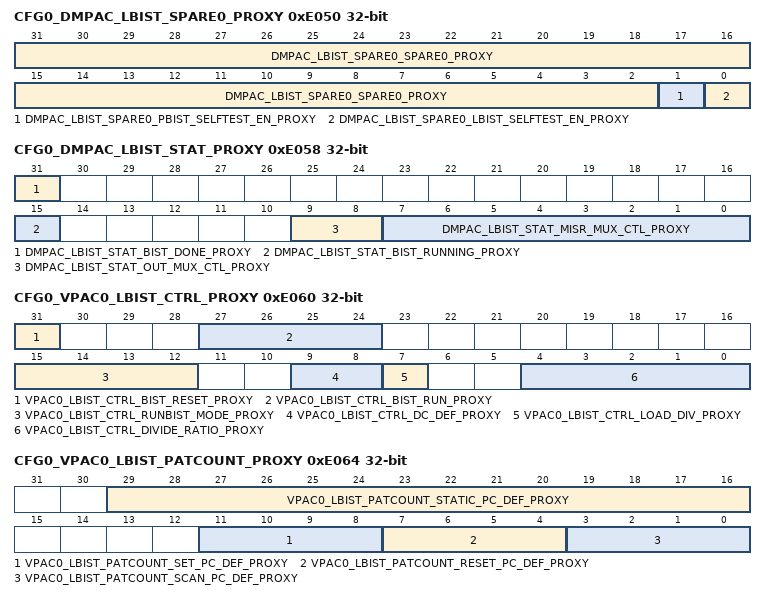
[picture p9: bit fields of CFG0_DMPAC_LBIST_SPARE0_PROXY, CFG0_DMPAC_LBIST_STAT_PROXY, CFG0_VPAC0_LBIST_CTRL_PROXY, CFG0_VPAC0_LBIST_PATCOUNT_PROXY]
0xE050 CFG0_DMPAC_LBIST_SPARE0_PROXY
  [31:2] DMPAC_LBIST_SPARE0_SPARE0_PROXY — LBIST spare bits
  [1] DMPAC_LBIST_SPARE0_PBIST_SELFTEST_EN_PROXY — PBIST isolation control
  [0] DMPAC_LBIST_SPARE0_LBIST_SELFTEST_EN_PROXY — LBIST isolation control
0xE054 CFG0_DMPAC_LBIST_SPARE1_PROXY
  [31:0] DMPAC_LBIST_SPARE1_SPARE1_PROXY — LBIST spare bits
0xE058 CFG0_DMPAC_LBIST_STAT_PROXY access per field
  [31] DMPAC_LBIST_STAT_BIST_DONE_PROXY ro — LBIST is done
  [15] DMPAC_LBIST_STAT_BIST_RUNNING_PROXY ro — LBIST is running
  [9:8] DMPAC_LBIST_STAT_OUT_MUX_CTL_PROXY rw — Selects source of LBIST output 00 - LBIST IP PID value 01 - LBIST CTRL ID value 1x - MISR value
  [7:0] DMPAC_LBIST_STAT_MISR_MUX_CTL_PROXY rw — Selects block of 32 MISR bits to read. A value of 0 selects a compacted 32-bit version of the full MISR. A value of 1-32 select a 32-bit segment of the MISR.
0xE05C CFG0_DMPAC_LBIST_MISR_PROXY ro
  [31:0] DMPAC_LBIST_MISR_MISR_RESULT_PROXY — 32-bits of MISR value selected by misr_mux_ctl
0xE060 CFG0_VPAC0_LBIST_CTRL_PROXY
  [31] VPAC0_LBIST_CTRL_BIST_RESET_PROXY — Reset LBIST macro
  [27:24] VPAC0_LBIST_CTRL_BIST_RUN_PROXY — Starts LBIST if all bits are 1
  [15:12] VPAC0_LBIST_CTRL_RUNBIST_MODE_PROXY — Runbist mode enable if all bits are 1
  [9:8] VPAC0_LBIST_CTRL_DC_DEF_PROXY — Clock delay after scan_enable switching
  [7] VPAC0_LBIST_CTRL_LOAD_DIV_PROXY — Loads LBIST clock divide ratio on transition from 0 to 1
  [4:0] VPAC0_LBIST_CTRL_DIVIDE_RATIO_PROXY — LBIST clock divide ratio
0xE064 CFG0_VPAC0_LBIST_PATCOUNT_PROXY
  [29:16] VPAC0_LBIST_PATCOUNT_STATIC_PC_DEF_PROXY — Number of stuck-at patterns to run
  [11:8] VPAC0_LBIST_PATCOUNT_SET_PC_DEF_PROXY — Number of set patterns to run
  [7:4] VPAC0_LBIST_PATCOUNT_RESET_PC_DEF_PROXY — Number of reset patterns to run
  [3:0] VPAC0_LBIST_PATCOUNT_SCAN_PC_DEF_PROXY — Number of chain test patterns to run
0xE068 CFG0_VPAC0_LBIST_SEED0_PROXY
  [31:0] VPAC0_LBIST_SEED0_PRPG_DEF_PROXY — Initial seed for PRPG (bits 31:0)
0xE06C CFG0_VPAC0_LBIST_SEED1_PROXY
  [20:0] VPAC0_LBIST_SEED1_PRPG_DEF_PROXY — Initial seed for PRPG (bits 52:32)
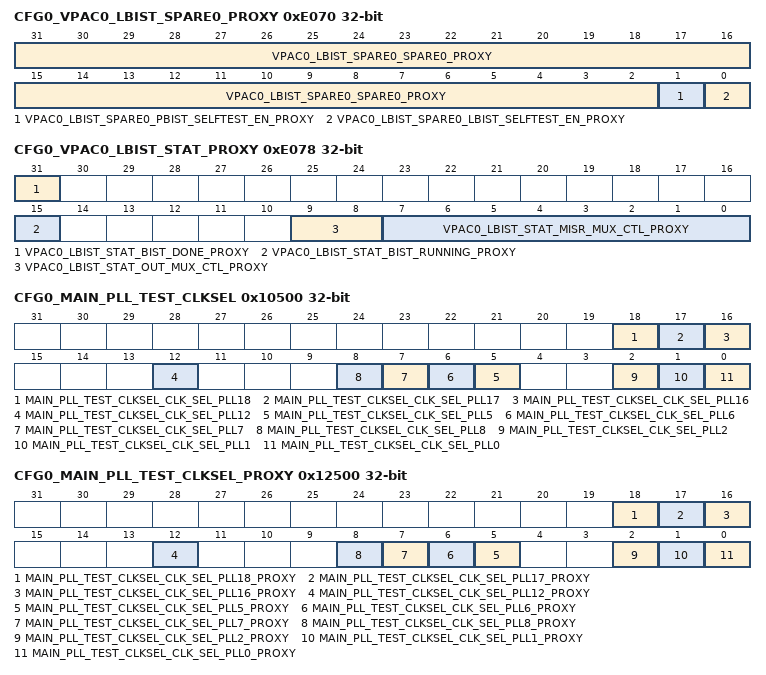
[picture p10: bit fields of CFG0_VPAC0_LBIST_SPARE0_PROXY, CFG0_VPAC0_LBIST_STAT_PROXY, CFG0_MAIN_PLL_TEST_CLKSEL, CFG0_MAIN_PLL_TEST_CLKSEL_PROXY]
0xE070 CFG0_VPAC0_LBIST_SPARE0_PROXY
  [31:2] VPAC0_LBIST_SPARE0_SPARE0_PROXY — LBIST spare bits
  [1] VPAC0_LBIST_SPARE0_PBIST_SELFTEST_EN_PROXY — PBIST isolation control
  [0] VPAC0_LBIST_SPARE0_LBIST_SELFTEST_EN_PROXY — LBIST isolation control
0xE074 CFG0_VPAC0_LBIST_SPARE1_PROXY
  [31:0] VPAC0_LBIST_SPARE1_SPARE1_PROXY — LBIST spare bits
0xE078 CFG0_VPAC0_LBIST_STAT_PROXY access per field
  [31] VPAC0_LBIST_STAT_BIST_DONE_PROXY ro — LBIST is done
  [15] VPAC0_LBIST_STAT_BIST_RUNNING_PROXY ro — LBIST is running
  [9:8] VPAC0_LBIST_STAT_OUT_MUX_CTL_PROXY rw — Selects source of LBIST output 00 - LBIST IP PID value 01 - LBIST CTRL ID value 1x - MISR value
  [7:0] VPAC0_LBIST_STAT_MISR_MUX_CTL_PROXY rw — Selects block of 32 MISR bits to read. A value of 0 selects a compacted 32-bit version of the full MISR. A value of 1-32 select a 32-bit segment of the MISR.
0xE07C CFG0_VPAC0_LBIST_MISR_PROXY ro
  [31:0] VPAC0_LBIST_MISR_MISR_RESULT_PROXY — 32-bits of MISR value selected by misr_mux_ctl
0xE288 CFG0_DMPAC_LBIST_SIG_PROXY ro
  [31:0] DMPAC_LBIST_SIG_MISR_SIG_PROXY — MISR signature
0xE28C CFG0_VPAC0_LBIST_SIG_PROXY ro
  [31:0] VPAC0_LBIST_SIG_MISR_SIG_PROXY — MISR signature
{0xF100+4i} CFG0_CLAIMREG_P3_R{i} (i=0..5)
  [31:0] CLAIMREG_P3_R{i} — Claim bits for Partition 3
0x10500 CFG0_MAIN_PLL_TEST_CLKSEL
  [18] MAIN_PLL_TEST_CLKSEL_CLK_SEL_PLL18 — Selects the alternate clock source for MAIN PLL18 Field values (others are reserved): 1'b0 - HFOSC0_CLKOUT 1'b1 - EXT_REFCLK1 (Pin)
  [17] MAIN_PLL_TEST_CLKSEL_CLK_SEL_PLL17 — Selects the alternate clock source for MAIN PLL17 Field values (others are reserved): 1'b0 - HFOSC0_CLKOUT 1'b1 - EXT_REFCLK1 (Pin)
  [16] MAIN_PLL_TEST_CLKSEL_CLK_SEL_PLL16 — Selects the alternate clock source for MAIN PLL16 Field values (others are reserved): 1'b0 - HFOSC0_CLKOUT 1'b1 - EXT_REFCLK1 (Pin)
  [12] MAIN_PLL_TEST_CLKSEL_CLK_SEL_PLL12 — Selects the alternate clock source for MAIN PLL12 Field values (others are reserved): 1'b0 - HFOSC0_CLKOUT 1'b1 - EXT_REFCLK1 (Pin)
  [n] MAIN_PLL_TEST_CLKSEL_CLK_SEL_PLL{n} (n=5..8) — Selects the alternate clock source for MAIN PLL{n} Field values (others are reserved): 1'b0 - HFOSC0_CLKOUT 1'b1 - EXT_REFCLK1 (Pin)
  [2] MAIN_PLL_TEST_CLKSEL_CLK_SEL_PLL2 — Selects the alternate clock source for MAIN PLL2 Field values (others are reserved): 1'b0 - HFOSC0_CLKOUT 1'b1 - EXT_REFCLK1 (Pin)
  [1] MAIN_PLL_TEST_CLKSEL_CLK_SEL_PLL1 — Selects the alternate clock source for MAIN PLL1 Field values (others are reserved): 1'b0 - HFOSC0_CLKOUT 1'b1 - EXT_REFCLK1 (Pin)
  [0] MAIN_PLL_TEST_CLKSEL_CLK_SEL_PLL0 — Selects the alternate clock source for MAIN PLL0 Field values (others are reserved): 1'b0 - HFOSC0_CLKOUT 1'b1 - EXT_REFCLK1 (Pin)
{0x11100+4i} CFG0_CLAIMREG_P4_R{i}_READONLY ro (i=0..10)
  [31:0] CLAIMREG_P4_R{i}_READONLY — Claim bits for Partition 4
0x12500 CFG0_MAIN_PLL_TEST_CLKSEL_PROXY
  [18] MAIN_PLL_TEST_CLKSEL_CLK_SEL_PLL18_PROXY — Selects the alternate clock source for MAIN PLL18 Field values (others are reserved): 1'b0 - HFOSC0_CLKOUT 1'b1 - EXT_REFCLK1 (Pin)
  [17] MAIN_PLL_TEST_CLKSEL_CLK_SEL_PLL17_PROXY — Selects the alternate clock source for MAIN PLL17 Field values (others are reserved): 1'b0 - HFOSC0_CLKOUT 1'b1 - EXT_REFCLK1 (Pin)
  [16] MAIN_PLL_TEST_CLKSEL_CLK_SEL_PLL16_PROXY — Selects the alternate clock source for MAIN PLL16 Field values (others are reserved): 1'b0 - HFOSC0_CLKOUT 1'b1 - EXT_REFCLK1 (Pin)
  [12] MAIN_PLL_TEST_CLKSEL_CLK_SEL_PLL12_PROXY — Selects the alternate clock source for MAIN PLL12 Field values (others are reserved): 1'b0 - HFOSC0_CLKOUT 1'b1 - EXT_REFCLK1 (Pin)
  [n] MAIN_PLL_TEST_CLKSEL_CLK_SEL_PLL{n}_PROXY (n=5..8) — Selects the alternate clock source for MAIN PLL{n} Field values (others are reserved): 1'b0 - HFOSC0_CLKOUT 1'b1 - EXT_REFCLK1 (Pin)
  [2] MAIN_PLL_TEST_CLKSEL_CLK_SEL_PLL2_PROXY — Selects the alternate clock source for MAIN PLL2 Field values (others are reserved): 1'b0 - HFOSC0_CLKOUT 1'b1 - EXT_REFCLK1 (Pin)
  [1] MAIN_PLL_TEST_CLKSEL_CLK_SEL_PLL1_PROXY — Selects the alternate clock source for MAIN PLL1 Field values (others are reserved): 1'b0 - HFOSC0_CLKOUT 1'b1 - EXT_REFCLK1 (Pin)
  [0] MAIN_PLL_TEST_CLKSEL_CLK_SEL_PLL0_PROXY — Selects the alternate clock source for MAIN PLL0 Field values (others are reserved): 1'b0 - HFOSC0_CLKOUT 1'b1 - EXT_REFCLK1 (Pin)
{0x13100+4i} CFG0_CLAIMREG_P4_R{i} (i=0..10)
  [31:0] CLAIMREG_P4_R{i} — Claim bits for Partition 4
0x19008 CFG0_LOCK6_KICK0
  [31:0] LOCK6_KICK0 — - KICK0 component
0x1900C CFG0_LOCK6_KICK1
  [31:0] LOCK6_KICK1 — - KICK1 component
{0x19100+4i} CFG0_CLAIMREG_P6_R{i}_READONLY ro (i=0..8)
  [31:0] CLAIMREG_P6_R{i}_READONLY — Claim bits for Partition 6
0x1B008 CFG0_LOCK6_KICK0_PROXY
  [31:0] LOCK6_KICK0_PROXY — - KICK0 component
0x1B00C CFG0_LOCK6_KICK1_PROXY
  [31:0] LOCK6_KICK1_PROXY — - KICK1 component
{0x1B100+4i} CFG0_CLAIMREG_P6_R{i} (i=0..8)
  [31:0] CLAIMREG_P6_R{i} — Claim bits for Partition 6
